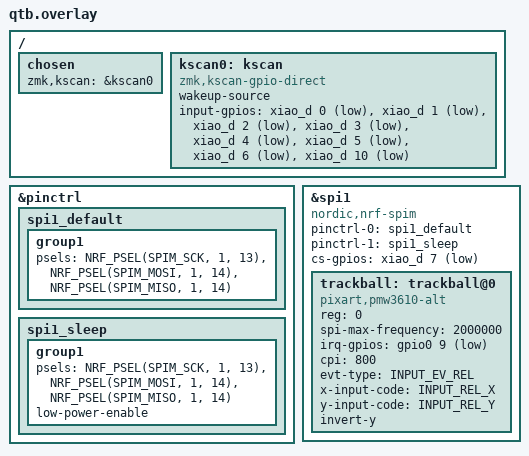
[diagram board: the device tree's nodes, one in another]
#include <zephyr/dt-bindings/input/input-event-codes.h>
#include <input/processors.dtsi>

/*
 * XIAO nRF52840 ピン割り当て
 *
 *  D0  / P0.02 : LCLK
 *  D1  / P0.03 : RCLK
 *  D2  / P0.28 : MCLK
 *  D3  / P0.29 : MB4
 *  D4  / P0.04 : MB5
 *  D5  / P0.05 : 左チルト
 *  D6  / P1.11 : 右チルト
 *  D7  / P1.12 : CS
 *  D8  / P1.13 : SCLK (ハードウェアSPI)
 *  D9  / P1.14 : SDIO (MOSI/MISO共通)
 *  D10 / P1.15 : スクロールレイヤー
 *  NFC1/ P0.09 : IRQ
 */

/ {
    chosen {
        zmk,kscan = &kscan0;
    };

    kscan0: kscan {
        compatible = "zmk,kscan-gpio-direct";
        wakeup-source;
        input-gpios
            = <&xiao_d 0  (GPIO_ACTIVE_LOW | GPIO_PULL_UP)>  /* LCLK             */
            , <&xiao_d 1  (GPIO_ACTIVE_LOW | GPIO_PULL_UP)>  /* RCLK             */
            , <&xiao_d 2  (GPIO_ACTIVE_LOW | GPIO_PULL_UP)>  /* MCLK             */
            , <&xiao_d 3  (GPIO_ACTIVE_LOW | GPIO_PULL_UP)>  /* MB4              */
            , <&xiao_d 4  (GPIO_ACTIVE_LOW | GPIO_PULL_UP)>  /* MB5              */
            , <&xiao_d 5  (GPIO_ACTIVE_LOW | GPIO_PULL_UP)>  /* 左チルト          */
            , <&xiao_d 6  (GPIO_ACTIVE_LOW | GPIO_PULL_UP)>  /* 右チルト          */
            , <&xiao_d 10 (GPIO_ACTIVE_LOW | GPIO_PULL_UP)>  /* スクロールレイヤー */
            ;
    };
};

&pinctrl {
    spi1_default: spi1_default {
        group1 {
            psels = <NRF_PSEL(SPIM_SCK,  1, 13)>,  /* D8 : SCLK */
                    <NRF_PSEL(SPIM_MOSI, 1, 14)>,  /* D9 : SDIO */
                    <NRF_PSEL(SPIM_MISO, 1, 14)>;  /* D9 : SDIO (同じピン) */
        };
    };
    spi1_sleep: spi1_sleep {
        group1 {
            psels = <NRF_PSEL(SPIM_SCK,  1, 13)>,
                    <NRF_PSEL(SPIM_MOSI, 1, 14)>,
                    <NRF_PSEL(SPIM_MISO, 1, 14)>;
            low-power-enable;
        };
    };
};

&spi1 {
    status = "okay";
    compatible = "nordic,nrf-spim";
    pinctrl-0 = <&spi1_default>;
    pinctrl-1 = <&spi1_sleep>;
    pinctrl-names = "default", "sleep";
    cs-gpios = <&xiao_d 7 GPIO_ACTIVE_LOW>;         /* D7 / P1.12 */

    trackball: trackball@0 {
        status = "okay";
        compatible = "pixart,pmw3610-alt";
        reg = <0>;
        spi-max-frequency = <2000000>;
        irq-gpios = <&gpio0 9 (GPIO_ACTIVE_LOW | GPIO_PULL_UP)>;
        cpi = <800>;
        evt-type = <INPUT_EV_REL>;
        x-input-code = <INPUT_REL_X>;
        y-input-code = <INPUT_REL_Y>;
        invert-y;
    };
};
